CM_ "AUTOGENERATED FILE, DO NOT EDIT"

CM_ "Imported file _toyota_2017.dbc starts here"
VERSION ""

NS_ :

BS_:

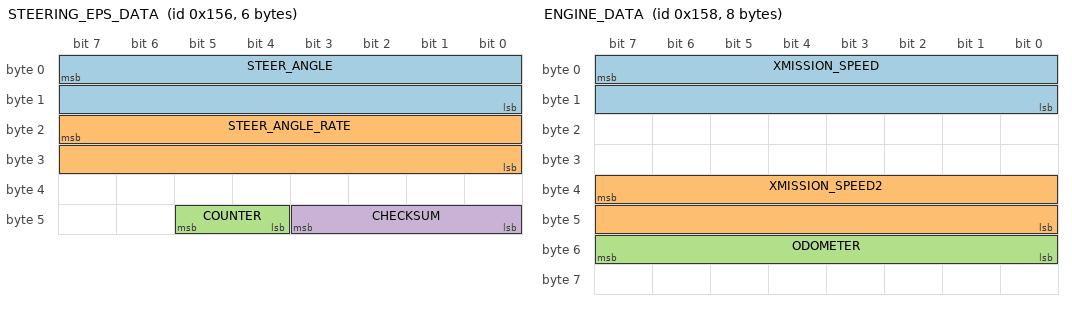
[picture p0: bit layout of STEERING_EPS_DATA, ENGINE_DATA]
BO_ 342 STEERING_EPS_DATA: 6 XXX
 SG_ STEER_ANGLE : 7|16@0- (-0.1,0) [-500|500] "deg" EON
 SG_ STEER_ANGLE_RATE : 23|16@0- (1,0) [-3000|3000] "deg/s" EON
 SG_ COUNTER : 45|2@0+ (1,0) [0|3] "" EON
 SG_ CHECKSUM : 43|4@0+ (1,0) [0|3] "" EON

BO_ 344 ENGINE_DATA: 8 PCM
 SG_ XMISSION_SPEED : 7|16@0+ (0.01,0) [0|250] "kph" EON
 SG_ XMISSION_SPEED2 : 39|16@0+ (0.01,0) [0|250] "kph" EON
 SG_ ODOMETER : 55|8@0+ (10,0) [0|2550] "m" XXX

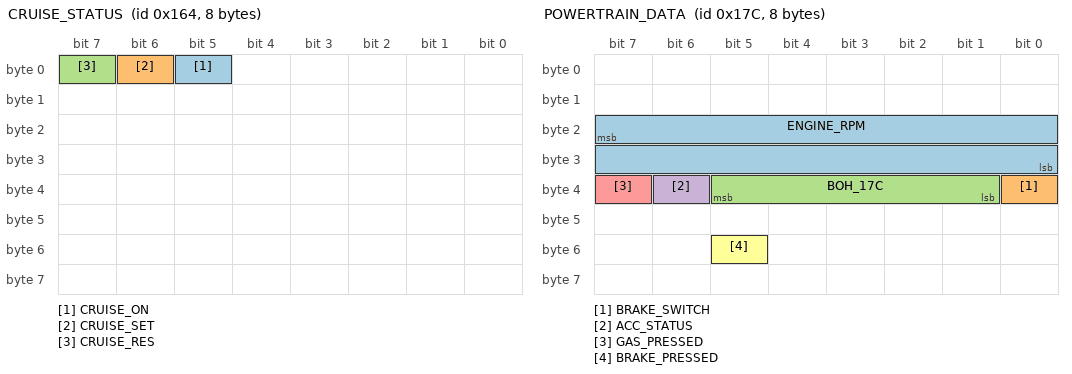
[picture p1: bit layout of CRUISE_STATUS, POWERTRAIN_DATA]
BO_ 356 CRUISE_STATUS: 8 XXX
 SG_ CRUISE_ON : 5|1@0+ (1,0) [0|1] "" XXX
 SG_ CRUISE_SET : 6|1@0+ (1,0) [0|1] "" XXX
 SG_ CRUISE_RES : 7|1@0+ (1,0) [0|1] "" XXX

BO_ 380 POWERTRAIN_DATA: 8 PCM
 SG_ ENGINE_RPM : 23|16@0+ (1,0) [0|15000] "rpm" EON
 SG_ BRAKE_SWITCH : 32|1@0+ (1,0) [0|1] "" EON
 SG_ BOH_17C : 37|5@0+ (1,0) [0|1] "" EON
 SG_ ACC_STATUS : 38|1@0+ (1,0) [0|1] "" EON
 SG_ GAS_PRESSED : 39|1@0+ (1,0) [0|1] "" EON
 SG_ BRAKE_PRESSED : 53|1@0+ (1,0) [0|1] "" EON

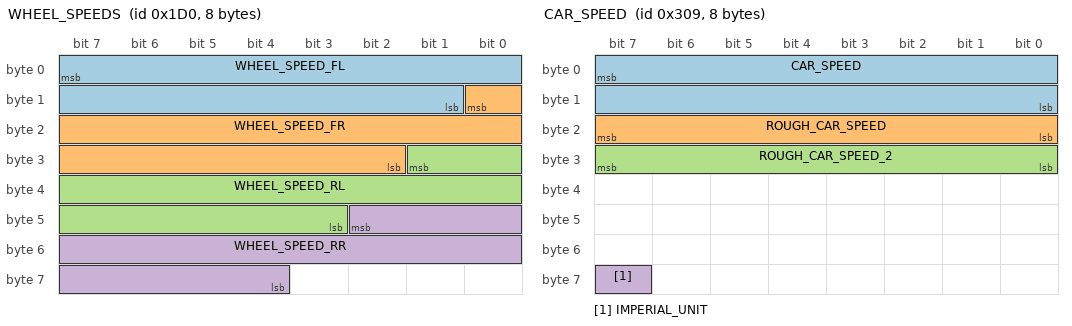
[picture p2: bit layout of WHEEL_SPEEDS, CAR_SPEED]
BO_ 464 WHEEL_SPEEDS: 8 VSA
 SG_ WHEEL_SPEED_FL : 7|15@0+ (0.01,0) [0|250] "kph" EON
 SG_ WHEEL_SPEED_FR : 8|15@0+ (0.01,0) [0|250] "kph" EON
 SG_ WHEEL_SPEED_RL : 25|15@0+ (0.01,0) [0|250] "kph" EON
 SG_ WHEEL_SPEED_RR : 42|15@0+ (0.01,0) [0|250] "kph" EON

BO_ 777 CAR_SPEED: 8 PCM
 SG_ CAR_SPEED : 7|16@0+ (0.01,0) [0|65535] "kph" XXX
 SG_ ROUGH_CAR_SPEED : 23|8@0+ (1,0) [0|255] "mph" XXX
 SG_ ROUGH_CAR_SPEED_2 : 31|8@0+ (1,0) [0|255] "mph" XXX
 SG_ IMPERIAL_UNIT : 63|1@0+ (1,0) [0|1] "" XXX

CM_ "CHFFR_METRIC 37 STEER_ANGLE STEER_ANGLE 0.36 180";

CM_ "toyota_corolla_2017_pt.dbc starts here"

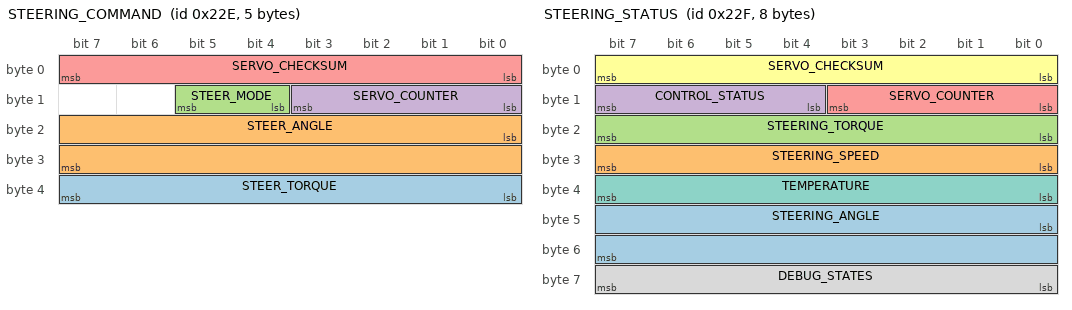
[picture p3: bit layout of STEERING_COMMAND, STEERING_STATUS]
BO_ 558 STEERING_COMMAND: 5 EON
 SG_ STEER_TORQUE : 32|8@1- (0.125,0) [-16|15.875] "Nm" EPAS
 SG_ STEER_ANGLE : 16|16@1- (0.125,0) [-4096|4095.875] "deg" EPAS
 SG_ STEER_MODE : 12|2@1+ (1,0) [0|3] "" EPAS
 SG_ SERVO_COUNTER : 8|4@1+ (1,0) [0|15] "" EPAS
 SG_ SERVO_CHECKSUM : 0|8@1+ (1,0) [0|255] "" EPAS

BO_ 559 STEERING_STATUS: 8 EPAS
 SG_ STEERING_ANGLE : 40|16@1- (0.125,0) [-4096|4095.875] "deg" EON
 SG_ STEERING_SPEED : 24|8@1- (0.015625,0) [-2|1.984375] "rev/s" EON
 SG_ STEERING_TORQUE : 16|8@1- (0.125,0) [-16|15.875] "Nm" EON
 SG_ CONTROL_STATUS : 12|4@1+ (1,0) [0|15] "" EON
 SG_ SERVO_COUNTER : 8|4@1+ (1,0) [0|15] "" EON
 SG_ SERVO_CHECKSUM : 0|8@1+ (1,0) [0|255] "" EON
 SG_ TEMPERATURE : 32|8@1+ (1,-60) [-60|195] "C" EON
 SG_ DEBUG_STATES : 56|8@1+ (1,0) [0|255] "" EON

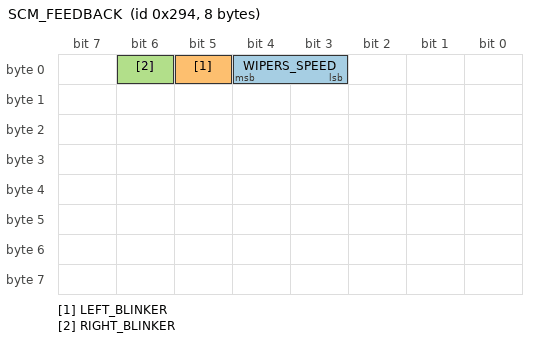
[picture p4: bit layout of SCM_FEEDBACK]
BO_ 660 SCM_FEEDBACK: 8 SCM
 SG_ WIPERS_SPEED : 4|2@0+ (1,0) [0|3] "" EON
 SG_ LEFT_BLINKER : 5|1@0+ (1,0) [0|1] "" EON
 SG_ RIGHT_BLINKER : 6|1@0+ (1,0) [0|1] "" EON

CM_ SG_ 558 STEER_TORQUE "Steering torque request";
CM_ SG_ 558 STEER_ANGLE "Steering relative angle request for internal close loop controller";
CM_ SG_ 558 STEER_MODE "Control mode request. 
Off - instant 0 torque.
TorqueControl - use steer_torque
RelativeControl - use steer_angle as relative target and steer_torque as feedforward. 
SoftOff - ramp torque to 0 in 1s. 
Command Off after SoftOff to re-enable control.";
CM_ SG_ 558 COUNTER "Rolling counter";
CM_ SG_ 558 CHECKSUM "8bit sum of all bytes and message id";
CM_ SG_ 559 STEERING_ANGLE "Steering angle calculated from motor position sensor";
CM_ SG_ 559 STEERING_SPEED "Steering speed calculated from motor position sensor";
CM_ SG_ 559 STEERING_TORQUE "Motor torque calculated at the steering";
CM_ SG_ 559 CONTROL_STATUS "Bitwise states: bit0 - sensored torque control is enabled, bit1 - sensor feedback enabled, bit2 - openloop soft off active, bit3 - internal closeloop mode enabled";
CM_ SG_ 559 COUNTER "Rolling counter";
CM_ SG_ 559 CHECKSUM "8bit sum of all bytes and message id";
CM_ SG_ 559 TEMPERATURE "Motor PCB temperature";
CM_ SG_ 559 DEBUG_STATES "Bitwise status. Refer to source";
VAL_ 558 STEER_MODE 0 "Off" 1 "TorqueControl" 2 "RelativeControl" 3 "SoftOff" ;
